AUTOSAR XML (schema 4-2-2)
package /ComponentTypes
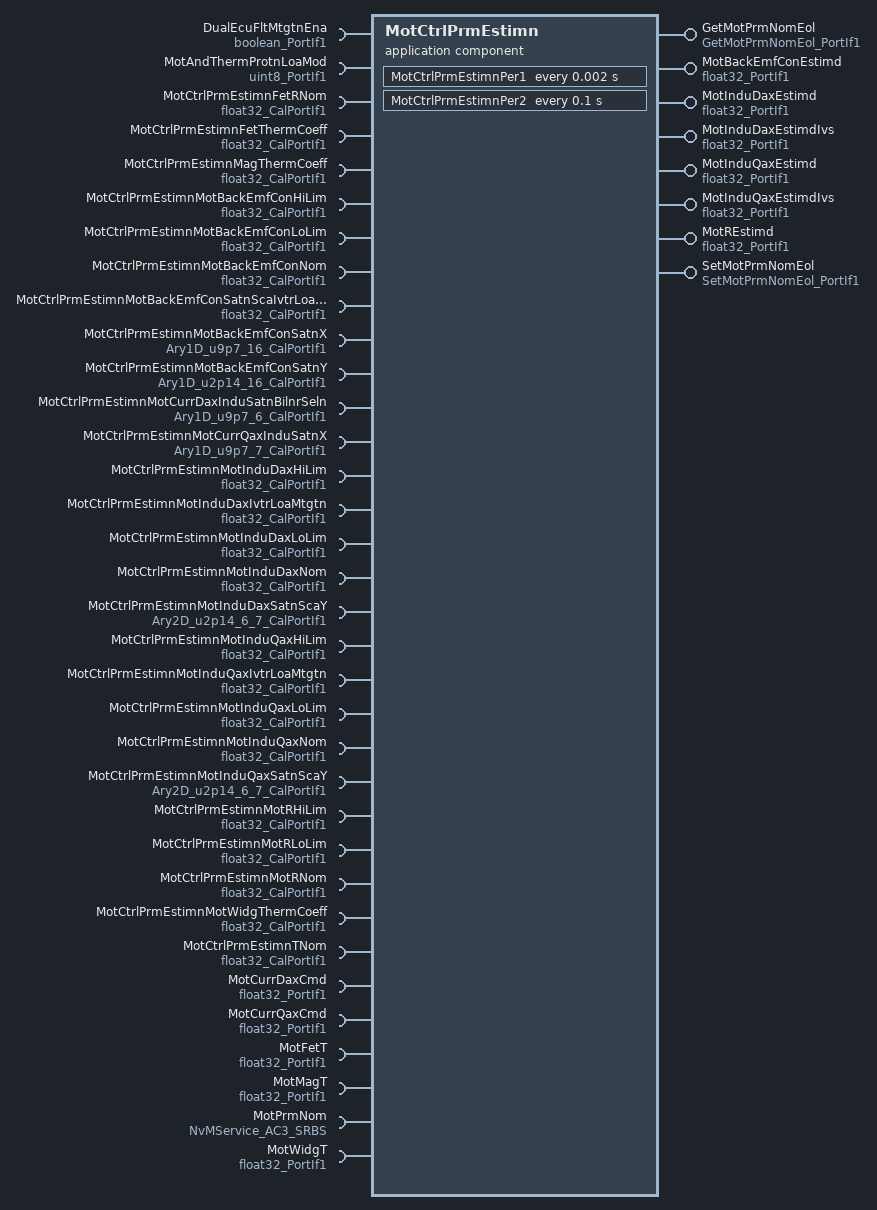
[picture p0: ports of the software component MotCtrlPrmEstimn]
  application sw component type MotCtrlPrmEstimn
    8 x provide port:
      GetMotPrmNomEol: server-com-spec{operation=Oper, queue-length=1}, provided-interface=GetMotPrmNomEol_PortIf1
      MotBackEmfConEstimd: nonqueued-sender-com-spec{data-element=Val, init-value=0.025}, provided-interface=float32_PortIf1
      MotInduDaxEstimd: nonqueued-sender-com-spec{data-element=Val, init-value=0.00011889}, provided-interface=float32_PortIf1
      MotInduDaxEstimdIvs: nonqueued-sender-com-spec{data-element=Val, init-value=8412}, provided-interface=float32_PortIf1
      MotInduQaxEstimd: nonqueued-sender-com-spec{data-element=Val, init-value=0.00011889}, provided-interface=float32_PortIf1
      MotInduQaxEstimdIvs: nonqueued-sender-com-spec{data-element=Val, init-value=8412}, provided-interface=float32_PortIf1
      MotREstimd: nonqueued-sender-com-spec{data-element=Val, init-value=0.005}, provided-interface=float32_PortIf1
      SetMotPrmNomEol: server-com-spec{operation=Oper, queue-length=1}, provided-interface=SetMotPrmNomEol_PortIf1
    34 x require port:
      DualEcuFltMtgtnEna: nonqueued-receiver-com-spec{data-element=Logl, filter=data-filter-type=ALWAYS, init-value=0}, required-interface=boolean_PortIf1
      MotAndThermProtnLoaMod: nonqueued-receiver-com-spec{data-element=Val, filter=data-filter-type=ALWAYS, init-value=0}, required-interface=uint8_PortIf1
      MotCtrlPrmEstimnFetRNom: parameter-require-com-spec{init-value=0.0052, parameter=Val}, required-interface=float32_CalPortIf1
      MotCtrlPrmEstimnFetThermCoeff: parameter-require-com-spec{init-value=0.005, parameter=Val}, required-interface=float32_CalPortIf1
      MotCtrlPrmEstimnMagThermCoeff: parameter-require-com-spec{init-value=-0.001, parameter=Val}, required-interface=float32_CalPortIf1
      MotCtrlPrmEstimnMotBackEmfConHiLim: parameter-require-com-spec{init-value=0.045, parameter=Val}, required-interface=float32_CalPortIf1
      MotCtrlPrmEstimnMotBackEmfConLoLim: parameter-require-com-spec{init-value=0.031, parameter=Val}, required-interface=float32_CalPortIf1
      MotCtrlPrmEstimnMotBackEmfConNom: parameter-require-com-spec{init-value=0.04, parameter=Val}, required-interface=float32_CalPortIf1
      MotCtrlPrmEstimnMotBackEmfConSatnScaIvtrLoaMtgtn: parameter-require-com-spec{init-value=1.0, parameter=Val}, required-interface=float32_CalPortIf1
      MotCtrlPrmEstimnMotBackEmfConSatnX: parameter-require-com-spec{init-value=[0, 1280, 2560, 3840, 5120, 6400, 7680, 8960, 10240, 11520, 12800, 14080, 15360, 16640, 19200, 21760], parameter=Ary1D}, required-interface=Ary1D_u9p7_16_CalPortIf1
      MotCtrlPrmEstimnMotBackEmfConSatnY: parameter-require-com-spec{init-value=[16384, 16384, 16384, 16384, 16384, 16384, 16384, 16384, 16384, 16384, 16384, 16370, 16336, 16276, 16095, 15869], parameter=Ary1D}, required-interface=Ary1D_u2p14_16_CalPortIf1
      MotCtrlPrmEstimnMotCurrDaxInduSatnBilnrSeln: parameter-require-com-spec{init-value=[0, 3200, 6400, 9600, 12800, 16000], parameter=Ary1D}, required-interface=Ary1D_u9p7_6_CalPortIf1
      MotCtrlPrmEstimnMotCurrQaxInduSatnX: parameter-require-com-spec{init-value=[0, 3200, 6400, 9600, 12800, 16000, 19200], parameter=Ary1D}, required-interface=Ary1D_u9p7_7_CalPortIf1
      MotCtrlPrmEstimnMotInduDaxHiLim: parameter-require-com-spec{init-value=0.00013, parameter=Val}, required-interface=float32_CalPortIf1
      MotCtrlPrmEstimnMotInduDaxIvtrLoaMtgtn: parameter-require-com-spec{init-value=0.00013, parameter=Val}, required-interface=float32_CalPortIf1
      MotCtrlPrmEstimnMotInduDaxLoLim: parameter-require-com-spec{init-value=0.0001, parameter=Val}, required-interface=float32_CalPortIf1
      MotCtrlPrmEstimnMotInduDaxNom: parameter-require-com-spec{init-value=0.00011889, parameter=Val}, required-interface=float32_CalPortIf1
      MotCtrlPrmEstimnMotInduDaxSatnScaY: parameter-require-com-spec{init-value=6 x [16384, 16384, 16384, 16384, 16384, 16305, 16096], parameter=Ary2D}, required-interface=Ary2D_u2p14_6_7_CalPortIf1
      MotCtrlPrmEstimnMotInduQaxHiLim: parameter-require-com-spec{init-value=0.00013, parameter=Val}, required-interface=float32_CalPortIf1
      MotCtrlPrmEstimnMotInduQaxIvtrLoaMtgtn: parameter-require-com-spec{init-value=0.00013, parameter=Val}, required-interface=float32_CalPortIf1
      MotCtrlPrmEstimnMotInduQaxLoLim: parameter-require-com-spec{init-value=0.0001, parameter=Val}, required-interface=float32_CalPortIf1
      MotCtrlPrmEstimnMotInduQaxNom: parameter-require-com-spec{init-value=0.00011889, parameter=Val}, required-interface=float32_CalPortIf1
      MotCtrlPrmEstimnMotInduQaxSatnScaY: parameter-require-com-spec{init-value=6 x [16384, 16384, 16384, 16384, 16384, 16305, 16096], parameter=Ary2D}, required-interface=Ary2D_u2p14_6_7_CalPortIf1
      MotCtrlPrmEstimnMotRHiLim: parameter-require-com-spec{init-value=0.032, parameter=Val}, required-interface=float32_CalPortIf1
      MotCtrlPrmEstimnMotRLoLim: parameter-require-com-spec{init-value=0.01246, parameter=Val}, required-interface=float32_CalPortIf1
      MotCtrlPrmEstimnMotRNom: parameter-require-com-spec{init-value=0.0139, parameter=Val}, required-interface=float32_CalPortIf1
      MotCtrlPrmEstimnMotWidgThermCoeff: parameter-require-com-spec{init-value=0.0039, parameter=Val}, required-interface=float32_CalPortIf1
      MotCtrlPrmEstimnTNom: parameter-require-com-spec{init-value=25, parameter=Val}, required-interface=float32_CalPortIf1
      MotCurrDaxCmd: nonqueued-receiver-com-spec{data-element=Val, filter=data-filter-type=ALWAYS, init-value=0}, required-interface=float32_PortIf1
      MotCurrQaxCmd: nonqueued-receiver-com-spec{data-element=Val, filter=data-filter-type=ALWAYS, init-value=0}, required-interface=float32_PortIf1
      MotFetT: nonqueued-receiver-com-spec{data-element=Val, filter=data-filter-type=ALWAYS, init-value=0}, required-interface=float32_PortIf1
      MotMagT: nonqueued-receiver-com-spec{data-element=Val, filter=data-filter-type=ALWAYS, init-value=0}, required-interface=float32_PortIf1
      MotPrmNom: required-com-specs=[EraseBlock, GetErrorStatus, InvalidateNvBlock, ReadBlock, SetRamBlockStatus, WriteBlock], required-interface=NvMService_AC3_SRBS
      MotWidgT: nonqueued-receiver-com-spec{data-element=Val, filter=data-filter-type=ALWAYS, init-value=0}, required-interface=float32_PortIf1
    behavior MotCtrlPrmEstimn_InternalBehavior: data-type-mapping=Nexteer
      ar-typed-per-instance-memorys:
        10 x data, all with sw-calibration-access=READ-ONLY:
          dMotCtrlPrmEstimnCtrlrREstimdPreLim: type=float32
          dMotCtrlPrmEstimnFetRFfEstimd: type=float32
          dMotCtrlPrmEstimnMotBackEmfConEstimdPreLim: type=float32
          dMotCtrlPrmEstimnMotBackEmfConEstimdSatnSca: type=float32
          dMotCtrlPrmEstimnMotInduEstimdPreLimDax: type=float32
          dMotCtrlPrmEstimnMotInduEstimdPreLimQax: type=float32
          dMotCtrlPrmEstimnMotInduEstimdSatnScaDax: type=float32
          dMotCtrlPrmEstimnMotInduEstimdSatnScaQax: type=float32
          dMotCtrlPrmEstimnMotRFfEstimd: type=float32
          MotPrmNom: type=MotPrmNomEolRec3
      operation invoked event OIT_GetMotPrmNomEol_Oper_GetMotPrmNomEol_Oper: start-on-event=GetMotPrmNomEol_Oper, operation=GetMotPrmNomEol.Oper
      init event MotCtrlPrmEstimn_InitEvent: start-on-event=MotCtrlPrmEstimnInit1
      timing event TMT_MotCtrlPrmEstimnPer1: start-on-event=MotCtrlPrmEstimnPer1, period=0.002
      timing event TMT_MotCtrlPrmEstimnPer2: start-on-event=MotCtrlPrmEstimnPer2, period=0.1
      operation invoked event OIT_SetMotPrmNomEol_Oper_SetMotPrmNomEol_Oper: start-on-event=SetMotPrmNomEol_Oper, operation=SetMotPrmNomEol.Oper
      explicit-inter-runnable-variables:
        data MotBackEmfConFf: type=float32, init-value=0.03993
      port-api-options:
        enable-take-address=false, error-handling=NO-TRANSFORMER-ERROR-HANDLING, indirect-api=false, port=DualEcuFltMtgtnEna
        enable-take-address=false, error-handling=NO-TRANSFORMER-ERROR-HANDLING, indirect-api=false, port=GetMotPrmNomEol
        enable-take-address=false, error-handling=NO-TRANSFORMER-ERROR-HANDLING, indirect-api=false, port=MotAndThermProtnLoaMod
        enable-take-address=false, error-handling=NO-TRANSFORMER-ERROR-HANDLING, indirect-api=false, port=MotBackEmfConEstimd
        enable-take-address=false, error-handling=NO-TRANSFORMER-ERROR-HANDLING, indirect-api=false, port=MotCtrlPrmEstimnFetRNom
        enable-take-address=false, error-handling=NO-TRANSFORMER-ERROR-HANDLING, indirect-api=false, port=MotCtrlPrmEstimnFetThermCoeff
        enable-take-address=false, error-handling=NO-TRANSFORMER-ERROR-HANDLING, indirect-api=false, port=MotCtrlPrmEstimnMagThermCoeff
        enable-take-address=false, error-handling=NO-TRANSFORMER-ERROR-HANDLING, indirect-api=false, port=MotCtrlPrmEstimnMotBackEmfConNom
        enable-take-address=false, error-handling=NO-TRANSFORMER-ERROR-HANDLING, indirect-api=false, port=MotCtrlPrmEstimnMotBackEmfConSatnScaIvtrLoaMtgtn
        enable-take-address=false, error-handling=NO-TRANSFORMER-ERROR-HANDLING, indirect-api=false, port=MotCtrlPrmEstimnMotBackEmfConSatnX
        enable-take-address=false, error-handling=NO-TRANSFORMER-ERROR-HANDLING, indirect-api=false, port=MotCtrlPrmEstimnMotBackEmfConSatnY
        enable-take-address=false, error-handling=NO-TRANSFORMER-ERROR-HANDLING, indirect-api=false, port=MotCtrlPrmEstimnMotCurrDaxInduSatnBilnrSeln
        enable-take-address=false, error-handling=NO-TRANSFORMER-ERROR-HANDLING, indirect-api=false, port=MotCtrlPrmEstimnMotCurrQaxInduSatnX
        enable-take-address=false, error-handling=NO-TRANSFORMER-ERROR-HANDLING, indirect-api=false, port=MotCtrlPrmEstimnMotInduDaxHiLim
        enable-take-address=false, error-handling=NO-TRANSFORMER-ERROR-HANDLING, indirect-api=false, port=MotCtrlPrmEstimnMotInduDaxIvtrLoaMtgtn
        enable-take-address=false, error-handling=NO-TRANSFORMER-ERROR-HANDLING, indirect-api=false, port=MotCtrlPrmEstimnMotInduDaxLoLim
        enable-take-address=false, error-handling=NO-TRANSFORMER-ERROR-HANDLING, indirect-api=false, port=MotCtrlPrmEstimnMotInduDaxNom
        enable-take-address=false, error-handling=NO-TRANSFORMER-ERROR-HANDLING, indirect-api=false, port=MotCtrlPrmEstimnMotInduDaxSatnScaY
        enable-take-address=false, error-handling=NO-TRANSFORMER-ERROR-HANDLING, indirect-api=false, port=MotCtrlPrmEstimnMotInduQaxHiLim
        enable-take-address=false, error-handling=NO-TRANSFORMER-ERROR-HANDLING, indirect-api=false, port=MotCtrlPrmEstimnMotInduQaxIvtrLoaMtgtn
        enable-take-address=false, error-handling=NO-TRANSFORMER-ERROR-HANDLING, indirect-api=false, port=MotCtrlPrmEstimnMotInduQaxLoLim
        enable-take-address=false, error-handling=NO-TRANSFORMER-ERROR-HANDLING, indirect-api=false, port=MotCtrlPrmEstimnMotInduQaxNom
        enable-take-address=false, error-handling=NO-TRANSFORMER-ERROR-HANDLING, indirect-api=false, port=MotCtrlPrmEstimnMotInduQaxSatnScaY
        enable-take-address=false, error-handling=NO-TRANSFORMER-ERROR-HANDLING, indirect-api=false, port=MotCtrlPrmEstimnMotRHiLim
        enable-take-address=false, error-handling=NO-TRANSFORMER-ERROR-HANDLING, indirect-api=false, port=MotCtrlPrmEstimnMotRLoLim
        enable-take-address=false, error-handling=NO-TRANSFORMER-ERROR-HANDLING, indirect-api=false, port=MotCtrlPrmEstimnMotRNom
        enable-take-address=false, error-handling=NO-TRANSFORMER-ERROR-HANDLING, indirect-api=false, port=MotCtrlPrmEstimnMotWidgThermCoeff
        enable-take-address=false, error-handling=NO-TRANSFORMER-ERROR-HANDLING, indirect-api=false, port=MotCtrlPrmEstimnTNom
        enable-take-address=false, error-handling=NO-TRANSFORMER-ERROR-HANDLING, indirect-api=false, port=MotCurrDaxCmd
        enable-take-address=false, error-handling=NO-TRANSFORMER-ERROR-HANDLING, indirect-api=false, port=MotCurrQaxCmd
        enable-take-address=false, error-handling=NO-TRANSFORMER-ERROR-HANDLING, indirect-api=false, port=MotFetT
        enable-take-address=false, error-handling=NO-TRANSFORMER-ERROR-HANDLING, indirect-api=false, port=MotInduDaxEstimd
        enable-take-address=false, error-handling=NO-TRANSFORMER-ERROR-HANDLING, indirect-api=false, port=MotInduDaxEstimdIvs
        enable-take-address=false, error-handling=NO-TRANSFORMER-ERROR-HANDLING, indirect-api=false, port=MotInduQaxEstimd
        enable-take-address=false, error-handling=NO-TRANSFORMER-ERROR-HANDLING, indirect-api=false, port=MotInduQaxEstimdIvs
        enable-take-address=false, error-handling=NO-TRANSFORMER-ERROR-HANDLING, indirect-api=false, port=MotMagT
        enable-take-address=false, error-handling=NO-TRANSFORMER-ERROR-HANDLING, indirect-api=false, port=MotPrmNom
        enable-take-address=false, error-handling=NO-TRANSFORMER-ERROR-HANDLING, indirect-api=false, port=MotREstimd
        enable-take-address=false, error-handling=NO-TRANSFORMER-ERROR-HANDLING, indirect-api=false, port=MotWidgT
        enable-take-address=false, error-handling=NO-TRANSFORMER-ERROR-HANDLING, indirect-api=false, port=SetMotPrmNomEol
      5 x runnable:
        GetMotPrmNomEol_Oper
        MotCtrlPrmEstimnInit1
          data-send-points:
            4 x access:
              SEND_MotBackEmfConEstimd_Val: accessed-variable=MotBackEmfConEstimd.Val
              SEND_MotInduDaxEstimd_Val: accessed-variable=MotInduDaxEstimd.Val
              SEND_MotInduQaxEstimd_Val: accessed-variable=MotInduQaxEstimd.Val
              SEND_MotREstimd_Val: accessed-variable=MotREstimd.Val
          sync call SC_MotPrmNom_GetErrorStatus: operation=MotPrmNom.GetErrorStatus, timeout=0
          sync call SC_MotPrmNom_SetRamBlockStatus: operation=MotPrmNom.SetRamBlockStatus, timeout=0
        MotCtrlPrmEstimnPer1
          data-receive-point-by-arguments:
            4 x access:
              REC_DualEcuFltMtgtnEna_Logl: accessed-variable=DualEcuFltMtgtnEna.Logl
              REC_MotAndThermProtnLoaMod_Val: accessed-variable=MotAndThermProtnLoaMod.Val
              REC_MotCurrDaxCmd_Val: accessed-variable=MotCurrDaxCmd.Val
              REC_MotCurrQaxCmd_Val: accessed-variable=MotCurrQaxCmd.Val
          data-send-points:
            5 x access:
              SEND_MotBackEmfConEstimd_Val: accessed-variable=MotBackEmfConEstimd.Val
              SEND_MotInduDaxEstimd_Val: accessed-variable=MotInduDaxEstimd.Val
              SEND_MotInduDaxEstimdIvs_Val: accessed-variable=MotInduDaxEstimdIvs.Val
              SEND_MotInduQaxEstimd_Val: accessed-variable=MotInduQaxEstimd.Val
              SEND_MotInduQaxEstimdIvs_Val: accessed-variable=MotInduQaxEstimdIvs.Val
          read-local-variables:
            access READ_MotBackEmfConFf: accessed-variable=MotBackEmfConFf
        MotCtrlPrmEstimnPer2
          data-receive-point-by-arguments:
            access REC_MotFetT_Val: accessed-variable=MotFetT.Val
            access REC_MotMagT_Val: accessed-variable=MotMagT.Val
            access REC_MotWidgT_Val: accessed-variable=MotWidgT.Val
          data-send-points:
            access SEND_MotREstimd_Val: accessed-variable=MotREstimd.Val
          written-local-variables:
            access WRITE_MotBackEmfConFf: accessed-variable=MotBackEmfConFf
        SetMotPrmNomEol_Oper
          sync call SC_MotPrmNom_SetRamBlockStatus: operation=MotPrmNom.SetRamBlockStatus, timeout=0
  swc implementation MotCtrlPrmEstimn_Implementation: behavior=MotCtrlPrmEstimn_InternalBehavior
    code-descriptors:
      code Default: artifact-descriptors=autosar-engineering-object={short-label=Default, category=SWSRC}
